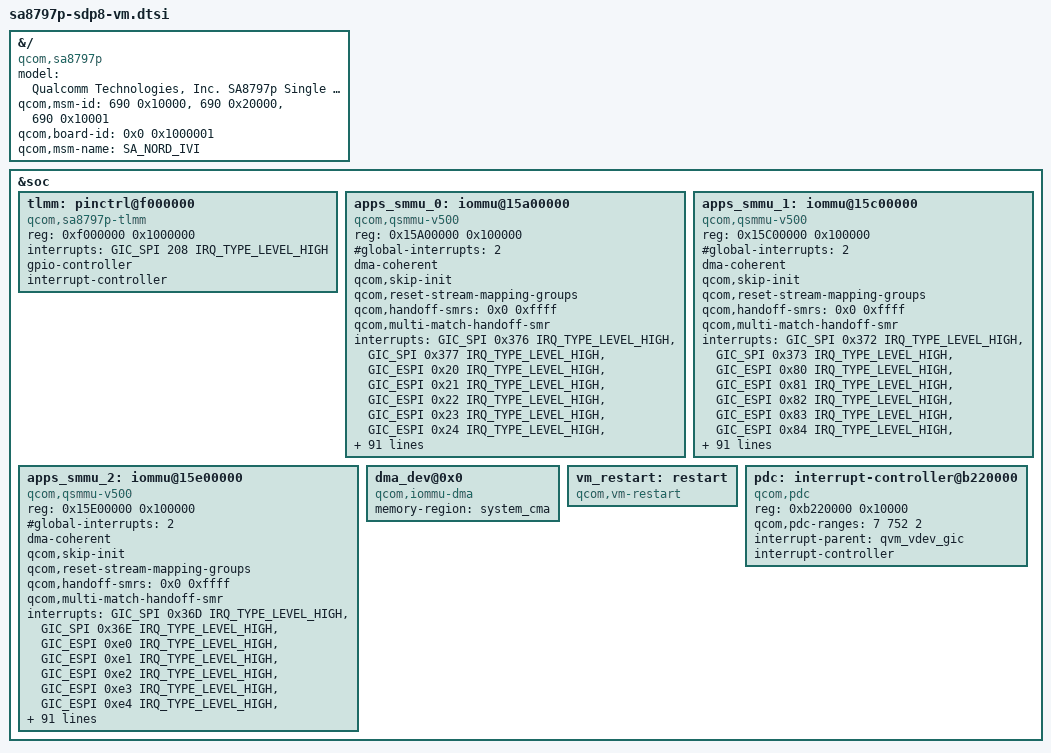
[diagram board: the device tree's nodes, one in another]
// SPDX-License-Identifier: BSD-3-Clause
/*
 * Copyright (c) Qualcomm Technologies, Inc. and/or its subsidiaries.
 */

#include "sdp8-quin-vm-common.dtsi"

&{/} {
	model = "Qualcomm Technologies, Inc. SA8797p Single LA  Guest Virtual Machine";
	compatible = "qcom,sa8797p", "qcom,quinvm";
	qcom,msm-id = <690 0x10000>, <690 0x20000>, <690 0x10001>;
	qcom,board-id = <0x0 0x1000001>;
	qcom,msm-name  = "SA_NORD_IVI";

	#address-cells = <2>;
	#size-cells = <2>;
};

&soc {
	tlmm: pinctrl@f000000 {
		compatible = "qcom,sa8797p-tlmm";
		reg = <0xf000000 0x1000000>;
		interrupts = <GIC_SPI 208 IRQ_TYPE_LEVEL_HIGH>;
		gpio-controller;
		#gpio-cells = <2>;
		interrupt-controller;
		#interrupt-cells = <2>;
	};

	apps_smmu_0: iommu@15a00000 {
		compatible = "qcom,qsmmu-v500";
		reg = <0x15A00000 0x100000>;
		reg-names = "base";
		#iommu-cells = <2>;
		#global-interrupts = <2>;
		dma-coherent;
		qcom,skip-init;
		qcom,reset-stream-mapping-groups;
		qcom,handoff-smrs = <0x0 0xffff>;
		qcom,multi-match-handoff-smr;
		interrupts = <GIC_SPI 0x376 IRQ_TYPE_LEVEL_HIGH>,
				<GIC_SPI 0x377 IRQ_TYPE_LEVEL_HIGH>,
				<GIC_ESPI 0x20 IRQ_TYPE_LEVEL_HIGH>,
				<GIC_ESPI 0x21 IRQ_TYPE_LEVEL_HIGH>,
				<GIC_ESPI 0x22 IRQ_TYPE_LEVEL_HIGH>,
				<GIC_ESPI 0x23 IRQ_TYPE_LEVEL_HIGH>,
				<GIC_ESPI 0x24 IRQ_TYPE_LEVEL_HIGH>,
				<GIC_ESPI 0x25 IRQ_TYPE_LEVEL_HIGH>,
				<GIC_ESPI 0x26 IRQ_TYPE_LEVEL_HIGH>,
				<GIC_ESPI 0x27 IRQ_TYPE_LEVEL_HIGH>,
				<GIC_ESPI 0x28 IRQ_TYPE_LEVEL_HIGH>,
				<GIC_ESPI 0x29 IRQ_TYPE_LEVEL_HIGH>,
				<GIC_ESPI 0x2A IRQ_TYPE_LEVEL_HIGH>,
				<GIC_ESPI 0x2B IRQ_TYPE_LEVEL_HIGH>,
				<GIC_ESPI 0x2C IRQ_TYPE_LEVEL_HIGH>,
				<GIC_ESPI 0x2D IRQ_TYPE_LEVEL_HIGH>,
				<GIC_ESPI 0x2E IRQ_TYPE_LEVEL_HIGH>,
				<GIC_ESPI 0x2F IRQ_TYPE_LEVEL_HIGH>,
				<GIC_ESPI 0x30 IRQ_TYPE_LEVEL_HIGH>,
				<GIC_ESPI 0x31 IRQ_TYPE_LEVEL_HIGH>,
				<GIC_ESPI 0x32 IRQ_TYPE_LEVEL_HIGH>,
				<GIC_ESPI 0x33 IRQ_TYPE_LEVEL_HIGH>,
				<GIC_ESPI 0x34 IRQ_TYPE_LEVEL_HIGH>,
				<GIC_ESPI 0x35 IRQ_TYPE_LEVEL_HIGH>,
				<GIC_ESPI 0x36 IRQ_TYPE_LEVEL_HIGH>,
				<GIC_ESPI 0x37 IRQ_TYPE_LEVEL_HIGH>,
				<GIC_ESPI 0x38 IRQ_TYPE_LEVEL_HIGH>,
				<GIC_ESPI 0x39 IRQ_TYPE_LEVEL_HIGH>,
				<GIC_ESPI 0x3A IRQ_TYPE_LEVEL_HIGH>,
				<GIC_ESPI 0x3B IRQ_TYPE_LEVEL_HIGH>,
				<GIC_ESPI 0x3C IRQ_TYPE_LEVEL_HIGH>,
				<GIC_ESPI 0x3D IRQ_TYPE_LEVEL_HIGH>,
				<GIC_ESPI 0x3E IRQ_TYPE_LEVEL_HIGH>,
				<GIC_ESPI 0x3F IRQ_TYPE_LEVEL_HIGH>,
				<GIC_ESPI 0x40 IRQ_TYPE_LEVEL_HIGH>,
				<GIC_ESPI 0x41 IRQ_TYPE_LEVEL_HIGH>,
				<GIC_ESPI 0x42 IRQ_TYPE_LEVEL_HIGH>,
				<GIC_ESPI 0x43 IRQ_TYPE_LEVEL_HIGH>,
				<GIC_ESPI 0x44 IRQ_TYPE_LEVEL_HIGH>,
				<GIC_ESPI 0x45 IRQ_TYPE_LEVEL_HIGH>,
				<GIC_ESPI 0x46 IRQ_TYPE_LEVEL_HIGH>,
				<GIC_ESPI 0x47 IRQ_TYPE_LEVEL_HIGH>,
				<GIC_ESPI 0x48 IRQ_TYPE_LEVEL_HIGH>,
				<GIC_ESPI 0x49 IRQ_TYPE_LEVEL_HIGH>,
				<GIC_ESPI 0x4A IRQ_TYPE_LEVEL_HIGH>,
				<GIC_ESPI 0x4B IRQ_TYPE_LEVEL_HIGH>,
				<GIC_ESPI 0x4C IRQ_TYPE_LEVEL_HIGH>,
				<GIC_ESPI 0x4D IRQ_TYPE_LEVEL_HIGH>,
				<GIC_ESPI 0x4E IRQ_TYPE_LEVEL_HIGH>,
				<GIC_ESPI 0x4F IRQ_TYPE_LEVEL_HIGH>,
				<GIC_ESPI 0x50 IRQ_TYPE_LEVEL_HIGH>,
				<GIC_ESPI 0x51 IRQ_TYPE_LEVEL_HIGH>,
				<GIC_ESPI 0x52 IRQ_TYPE_LEVEL_HIGH>,
				<GIC_ESPI 0x53 IRQ_TYPE_LEVEL_HIGH>,
				<GIC_ESPI 0x54 IRQ_TYPE_LEVEL_HIGH>,
				<GIC_ESPI 0x55 IRQ_TYPE_LEVEL_HIGH>,
				<GIC_ESPI 0x56 IRQ_TYPE_LEVEL_HIGH>,
				<GIC_ESPI 0x57 IRQ_TYPE_LEVEL_HIGH>,
				<GIC_ESPI 0x58 IRQ_TYPE_LEVEL_HIGH>,
				<GIC_ESPI 0x59 IRQ_TYPE_LEVEL_HIGH>,
				<GIC_ESPI 0x5A IRQ_TYPE_LEVEL_HIGH>,
				<GIC_ESPI 0x5B IRQ_TYPE_LEVEL_HIGH>,
				<GIC_ESPI 0x5C IRQ_TYPE_LEVEL_HIGH>,
				<GIC_ESPI 0x5D IRQ_TYPE_LEVEL_HIGH>,
				<GIC_ESPI 0x5E IRQ_TYPE_LEVEL_HIGH>,
				<GIC_ESPI 0x5F IRQ_TYPE_LEVEL_HIGH>,
				<GIC_ESPI 0x60 IRQ_TYPE_LEVEL_HIGH>,
				<GIC_ESPI 0x61 IRQ_TYPE_LEVEL_HIGH>,
				<GIC_ESPI 0x62 IRQ_TYPE_LEVEL_HIGH>,
				<GIC_ESPI 0x63 IRQ_TYPE_LEVEL_HIGH>,
				<GIC_ESPI 0x64 IRQ_TYPE_LEVEL_HIGH>,
				<GIC_ESPI 0x65 IRQ_TYPE_LEVEL_HIGH>,
				<GIC_ESPI 0x66 IRQ_TYPE_LEVEL_HIGH>,
				<GIC_ESPI 0x67 IRQ_TYPE_LEVEL_HIGH>,
				<GIC_ESPI 0x68 IRQ_TYPE_LEVEL_HIGH>,
				<GIC_ESPI 0x69 IRQ_TYPE_LEVEL_HIGH>,
				<GIC_ESPI 0x6A IRQ_TYPE_LEVEL_HIGH>,
				<GIC_ESPI 0x6B IRQ_TYPE_LEVEL_HIGH>,
				<GIC_ESPI 0x6C IRQ_TYPE_LEVEL_HIGH>,
				<GIC_ESPI 0x6D IRQ_TYPE_LEVEL_HIGH>,
				<GIC_ESPI 0x6E IRQ_TYPE_LEVEL_HIGH>,
				<GIC_ESPI 0x6F IRQ_TYPE_LEVEL_HIGH>,
				<GIC_ESPI 0x70 IRQ_TYPE_LEVEL_HIGH>,
				<GIC_ESPI 0x71 IRQ_TYPE_LEVEL_HIGH>,
				<GIC_ESPI 0x72 IRQ_TYPE_LEVEL_HIGH>,
				<GIC_ESPI 0x73 IRQ_TYPE_LEVEL_HIGH>,
				<GIC_ESPI 0x74 IRQ_TYPE_LEVEL_HIGH>,
				<GIC_ESPI 0x75 IRQ_TYPE_LEVEL_HIGH>,
				<GIC_ESPI 0x76 IRQ_TYPE_LEVEL_HIGH>,
				<GIC_ESPI 0x77 IRQ_TYPE_LEVEL_HIGH>,
				<GIC_ESPI 0x78 IRQ_TYPE_LEVEL_HIGH>,
				<GIC_ESPI 0x79 IRQ_TYPE_LEVEL_HIGH>,
				<GIC_ESPI 0x7A IRQ_TYPE_LEVEL_HIGH>,
				<GIC_ESPI 0x7B IRQ_TYPE_LEVEL_HIGH>,
				<GIC_ESPI 0x7C IRQ_TYPE_LEVEL_HIGH>,
				<GIC_ESPI 0x7D IRQ_TYPE_LEVEL_HIGH>,
				<GIC_ESPI 0x7E IRQ_TYPE_LEVEL_HIGH>,
				<GIC_ESPI 0x7F IRQ_TYPE_LEVEL_HIGH>;
	};

	apps_smmu_1: iommu@15c00000 {
		compatible = "qcom,qsmmu-v500";
		reg = <0x15C00000 0x100000>;
		reg-names = "base";
		#iommu-cells = <2>;
		#global-interrupts = <2>;
		dma-coherent;
		qcom,skip-init;
		qcom,reset-stream-mapping-groups;
		qcom,handoff-smrs = <0x0 0xffff>;
		qcom,multi-match-handoff-smr;
		interrupts = <GIC_SPI  0x372 IRQ_TYPE_LEVEL_HIGH>,
				<GIC_SPI  0x373 IRQ_TYPE_LEVEL_HIGH>,
				<GIC_ESPI 0x80 IRQ_TYPE_LEVEL_HIGH>,
				<GIC_ESPI 0x81 IRQ_TYPE_LEVEL_HIGH>,
				<GIC_ESPI 0x82 IRQ_TYPE_LEVEL_HIGH>,
				<GIC_ESPI 0x83 IRQ_TYPE_LEVEL_HIGH>,
				<GIC_ESPI 0x84 IRQ_TYPE_LEVEL_HIGH>,
				<GIC_ESPI 0x85 IRQ_TYPE_LEVEL_HIGH>,
				<GIC_ESPI 0x86 IRQ_TYPE_LEVEL_HIGH>,
				<GIC_ESPI 0x87 IRQ_TYPE_LEVEL_HIGH>,
				<GIC_ESPI 0x88 IRQ_TYPE_LEVEL_HIGH>,
				<GIC_ESPI 0x89 IRQ_TYPE_LEVEL_HIGH>,
				<GIC_ESPI 0x8a IRQ_TYPE_LEVEL_HIGH>,
				<GIC_ESPI 0x8b IRQ_TYPE_LEVEL_HIGH>,
				<GIC_ESPI 0x8c IRQ_TYPE_LEVEL_HIGH>,
				<GIC_ESPI 0x8d IRQ_TYPE_LEVEL_HIGH>,
				<GIC_ESPI 0x8e IRQ_TYPE_LEVEL_HIGH>,
				<GIC_ESPI 0x8f IRQ_TYPE_LEVEL_HIGH>,
				<GIC_ESPI 0x90 IRQ_TYPE_LEVEL_HIGH>,
				<GIC_ESPI 0x91 IRQ_TYPE_LEVEL_HIGH>,
				<GIC_ESPI 0x92 IRQ_TYPE_LEVEL_HIGH>,
				<GIC_ESPI 0x93 IRQ_TYPE_LEVEL_HIGH>,
				<GIC_ESPI 0x94 IRQ_TYPE_LEVEL_HIGH>,
				<GIC_ESPI 0x95 IRQ_TYPE_LEVEL_HIGH>,
				<GIC_ESPI 0x96 IRQ_TYPE_LEVEL_HIGH>,
				<GIC_ESPI 0x97 IRQ_TYPE_LEVEL_HIGH>,
				<GIC_ESPI 0x98 IRQ_TYPE_LEVEL_HIGH>,
				<GIC_ESPI 0x99 IRQ_TYPE_LEVEL_HIGH>,
				<GIC_ESPI 0x9a IRQ_TYPE_LEVEL_HIGH>,
				<GIC_ESPI 0x9b IRQ_TYPE_LEVEL_HIGH>,
				<GIC_ESPI 0x9c IRQ_TYPE_LEVEL_HIGH>,
				<GIC_ESPI 0x9d IRQ_TYPE_LEVEL_HIGH>,
				<GIC_ESPI 0x9e IRQ_TYPE_LEVEL_HIGH>,
				<GIC_ESPI 0x9f IRQ_TYPE_LEVEL_HIGH>,
				<GIC_ESPI 0xa0 IRQ_TYPE_LEVEL_HIGH>,
				<GIC_ESPI 0xa1 IRQ_TYPE_LEVEL_HIGH>,
				<GIC_ESPI 0xa2 IRQ_TYPE_LEVEL_HIGH>,
				<GIC_ESPI 0xa3 IRQ_TYPE_LEVEL_HIGH>,
				<GIC_ESPI 0xa4 IRQ_TYPE_LEVEL_HIGH>,
				<GIC_ESPI 0xa5 IRQ_TYPE_LEVEL_HIGH>,
				<GIC_ESPI 0xa6 IRQ_TYPE_LEVEL_HIGH>,
				<GIC_ESPI 0xa7 IRQ_TYPE_LEVEL_HIGH>,
				<GIC_ESPI 0xa8 IRQ_TYPE_LEVEL_HIGH>,
				<GIC_ESPI 0xa9 IRQ_TYPE_LEVEL_HIGH>,
				<GIC_ESPI 0xaa IRQ_TYPE_LEVEL_HIGH>,
				<GIC_ESPI 0xab IRQ_TYPE_LEVEL_HIGH>,
				<GIC_ESPI 0xac IRQ_TYPE_LEVEL_HIGH>,
				<GIC_ESPI 0xad IRQ_TYPE_LEVEL_HIGH>,
				<GIC_ESPI 0xae IRQ_TYPE_LEVEL_HIGH>,
				<GIC_ESPI 0xaf IRQ_TYPE_LEVEL_HIGH>,
				<GIC_ESPI 0xb0 IRQ_TYPE_LEVEL_HIGH>,
				<GIC_ESPI 0xb1 IRQ_TYPE_LEVEL_HIGH>,
				<GIC_ESPI 0xb2 IRQ_TYPE_LEVEL_HIGH>,
				<GIC_ESPI 0xb3 IRQ_TYPE_LEVEL_HIGH>,
				<GIC_ESPI 0xb4 IRQ_TYPE_LEVEL_HIGH>,
				<GIC_ESPI 0xb5 IRQ_TYPE_LEVEL_HIGH>,
				<GIC_ESPI 0xb6 IRQ_TYPE_LEVEL_HIGH>,
				<GIC_ESPI 0xb7 IRQ_TYPE_LEVEL_HIGH>,
				<GIC_ESPI 0xb8 IRQ_TYPE_LEVEL_HIGH>,
				<GIC_ESPI 0xb9 IRQ_TYPE_LEVEL_HIGH>,
				<GIC_ESPI 0xba IRQ_TYPE_LEVEL_HIGH>,
				<GIC_ESPI 0xbb IRQ_TYPE_LEVEL_HIGH>,
				<GIC_ESPI 0xbc IRQ_TYPE_LEVEL_HIGH>,
				<GIC_ESPI 0xbd IRQ_TYPE_LEVEL_HIGH>,
				<GIC_ESPI 0xbe IRQ_TYPE_LEVEL_HIGH>,
				<GIC_ESPI 0xbf IRQ_TYPE_LEVEL_HIGH>,
				<GIC_ESPI 0xc0 IRQ_TYPE_LEVEL_HIGH>,
				<GIC_ESPI 0xc1 IRQ_TYPE_LEVEL_HIGH>,
				<GIC_ESPI 0xc2 IRQ_TYPE_LEVEL_HIGH>,
				<GIC_ESPI 0xc3 IRQ_TYPE_LEVEL_HIGH>,
				<GIC_ESPI 0xc4 IRQ_TYPE_LEVEL_HIGH>,
				<GIC_ESPI 0xc5 IRQ_TYPE_LEVEL_HIGH>,
				<GIC_ESPI 0xc6 IRQ_TYPE_LEVEL_HIGH>,
				<GIC_ESPI 0xc7 IRQ_TYPE_LEVEL_HIGH>,
				<GIC_ESPI 0xc8 IRQ_TYPE_LEVEL_HIGH>,
				<GIC_ESPI 0xc9 IRQ_TYPE_LEVEL_HIGH>,
				<GIC_ESPI 0xca IRQ_TYPE_LEVEL_HIGH>,
				<GIC_ESPI 0xcb IRQ_TYPE_LEVEL_HIGH>,
				<GIC_ESPI 0xcc IRQ_TYPE_LEVEL_HIGH>,
				<GIC_ESPI 0xcd IRQ_TYPE_LEVEL_HIGH>,
				<GIC_ESPI 0xce IRQ_TYPE_LEVEL_HIGH>,
				<GIC_ESPI 0xcf IRQ_TYPE_LEVEL_HIGH>,
				<GIC_ESPI 0xd0 IRQ_TYPE_LEVEL_HIGH>,
				<GIC_ESPI 0xd1 IRQ_TYPE_LEVEL_HIGH>,
				<GIC_ESPI 0xd2 IRQ_TYPE_LEVEL_HIGH>,
				<GIC_ESPI 0xd3 IRQ_TYPE_LEVEL_HIGH>,
				<GIC_ESPI 0xd4 IRQ_TYPE_LEVEL_HIGH>,
				<GIC_ESPI 0xd5 IRQ_TYPE_LEVEL_HIGH>,
				<GIC_ESPI 0xd6 IRQ_TYPE_LEVEL_HIGH>,
				<GIC_ESPI 0xd7 IRQ_TYPE_LEVEL_HIGH>,
				<GIC_ESPI 0xd8 IRQ_TYPE_LEVEL_HIGH>,
				<GIC_ESPI 0xd9 IRQ_TYPE_LEVEL_HIGH>,
				<GIC_ESPI 0xda IRQ_TYPE_LEVEL_HIGH>,
				<GIC_ESPI 0xdb IRQ_TYPE_LEVEL_HIGH>,
				<GIC_ESPI 0xdc IRQ_TYPE_LEVEL_HIGH>,
				<GIC_ESPI 0xdd IRQ_TYPE_LEVEL_HIGH>,
				<GIC_ESPI 0xde IRQ_TYPE_LEVEL_HIGH>,
				<GIC_ESPI 0xdf IRQ_TYPE_LEVEL_HIGH>;
	};

	apps_smmu_2: iommu@15e00000 {
		compatible = "qcom,qsmmu-v500";
		reg = <0x15E00000 0x100000>;
		reg-names = "base";
		#iommu-cells = <2>;
		#global-interrupts = <2>;
		dma-coherent;
		qcom,skip-init;
		qcom,reset-stream-mapping-groups;
		qcom,handoff-smrs = <0x0 0xffff>;
		qcom,multi-match-handoff-smr;
		interrupts = <GIC_SPI  0x36D IRQ_TYPE_LEVEL_HIGH>,
				<GIC_SPI  0x36E IRQ_TYPE_LEVEL_HIGH>,
				<GIC_ESPI 0xe0 IRQ_TYPE_LEVEL_HIGH>,
				<GIC_ESPI 0xe1 IRQ_TYPE_LEVEL_HIGH>,
				<GIC_ESPI 0xe2 IRQ_TYPE_LEVEL_HIGH>,
				<GIC_ESPI 0xe3 IRQ_TYPE_LEVEL_HIGH>,
				<GIC_ESPI 0xe4 IRQ_TYPE_LEVEL_HIGH>,
				<GIC_ESPI 0xe5 IRQ_TYPE_LEVEL_HIGH>,
				<GIC_ESPI 0xe6 IRQ_TYPE_LEVEL_HIGH>,
				<GIC_ESPI 0xe7 IRQ_TYPE_LEVEL_HIGH>,
				<GIC_ESPI 0xe8 IRQ_TYPE_LEVEL_HIGH>,
				<GIC_ESPI 0xe9 IRQ_TYPE_LEVEL_HIGH>,
				<GIC_ESPI 0xea IRQ_TYPE_LEVEL_HIGH>,
				<GIC_ESPI 0xeb IRQ_TYPE_LEVEL_HIGH>,
				<GIC_ESPI 0xec IRQ_TYPE_LEVEL_HIGH>,
				<GIC_ESPI 0xed IRQ_TYPE_LEVEL_HIGH>,
				<GIC_ESPI 0xee IRQ_TYPE_LEVEL_HIGH>,
				<GIC_ESPI 0xef IRQ_TYPE_LEVEL_HIGH>,
				<GIC_ESPI 0xf0 IRQ_TYPE_LEVEL_HIGH>,
				<GIC_ESPI 0xf1 IRQ_TYPE_LEVEL_HIGH>,
				<GIC_ESPI 0xf2 IRQ_TYPE_LEVEL_HIGH>,
				<GIC_ESPI 0xf3 IRQ_TYPE_LEVEL_HIGH>,
				<GIC_ESPI 0xf4 IRQ_TYPE_LEVEL_HIGH>,
				<GIC_ESPI 0xf5 IRQ_TYPE_LEVEL_HIGH>,
				<GIC_ESPI 0xf6 IRQ_TYPE_LEVEL_HIGH>,
				<GIC_ESPI 0xf7 IRQ_TYPE_LEVEL_HIGH>,
				<GIC_ESPI 0xf8 IRQ_TYPE_LEVEL_HIGH>,
				<GIC_ESPI 0xf9 IRQ_TYPE_LEVEL_HIGH>,
				<GIC_ESPI 0xfa IRQ_TYPE_LEVEL_HIGH>,
				<GIC_ESPI 0xfb IRQ_TYPE_LEVEL_HIGH>,
				<GIC_ESPI 0xfc IRQ_TYPE_LEVEL_HIGH>,
				<GIC_ESPI 0xfd IRQ_TYPE_LEVEL_HIGH>,
				<GIC_ESPI 0xfe IRQ_TYPE_LEVEL_HIGH>,
				<GIC_ESPI 0xff IRQ_TYPE_LEVEL_HIGH>,
				<GIC_ESPI 0x100 IRQ_TYPE_LEVEL_HIGH>,
				<GIC_ESPI 0x101 IRQ_TYPE_LEVEL_HIGH>,
				<GIC_ESPI 0x102 IRQ_TYPE_LEVEL_HIGH>,
				<GIC_ESPI 0x103 IRQ_TYPE_LEVEL_HIGH>,
				<GIC_ESPI 0x104 IRQ_TYPE_LEVEL_HIGH>,
				<GIC_ESPI 0x105 IRQ_TYPE_LEVEL_HIGH>,
				<GIC_ESPI 0x106 IRQ_TYPE_LEVEL_HIGH>,
				<GIC_ESPI 0x107 IRQ_TYPE_LEVEL_HIGH>,
				<GIC_ESPI 0x108 IRQ_TYPE_LEVEL_HIGH>,
				<GIC_ESPI 0x109 IRQ_TYPE_LEVEL_HIGH>,
				<GIC_ESPI 0x10a IRQ_TYPE_LEVEL_HIGH>,
				<GIC_ESPI 0x10b IRQ_TYPE_LEVEL_HIGH>,
				<GIC_ESPI 0x10c IRQ_TYPE_LEVEL_HIGH>,
				<GIC_ESPI 0x10d IRQ_TYPE_LEVEL_HIGH>,
				<GIC_ESPI 0x10e IRQ_TYPE_LEVEL_HIGH>,
				<GIC_ESPI 0x10f IRQ_TYPE_LEVEL_HIGH>,
				<GIC_ESPI 0x110 IRQ_TYPE_LEVEL_HIGH>,
				<GIC_ESPI 0x111 IRQ_TYPE_LEVEL_HIGH>,
				<GIC_ESPI 0x112 IRQ_TYPE_LEVEL_HIGH>,
				<GIC_ESPI 0x113 IRQ_TYPE_LEVEL_HIGH>,
				<GIC_ESPI 0x114 IRQ_TYPE_LEVEL_HIGH>,
				<GIC_ESPI 0x115 IRQ_TYPE_LEVEL_HIGH>,
				<GIC_ESPI 0x116 IRQ_TYPE_LEVEL_HIGH>,
				<GIC_ESPI 0x117 IRQ_TYPE_LEVEL_HIGH>,
				<GIC_ESPI 0x118 IRQ_TYPE_LEVEL_HIGH>,
				<GIC_ESPI 0x119 IRQ_TYPE_LEVEL_HIGH>,
				<GIC_ESPI 0x11a IRQ_TYPE_LEVEL_HIGH>,
				<GIC_ESPI 0x11b IRQ_TYPE_LEVEL_HIGH>,
				<GIC_ESPI 0x11c IRQ_TYPE_LEVEL_HIGH>,
				<GIC_ESPI 0x11d IRQ_TYPE_LEVEL_HIGH>,
				<GIC_ESPI 0x11e IRQ_TYPE_LEVEL_HIGH>,
				<GIC_ESPI 0x11f IRQ_TYPE_LEVEL_HIGH>,
				<GIC_ESPI 0x120 IRQ_TYPE_LEVEL_HIGH>,
				<GIC_ESPI 0x121 IRQ_TYPE_LEVEL_HIGH>,
				<GIC_ESPI 0x122 IRQ_TYPE_LEVEL_HIGH>,
				<GIC_ESPI 0x123 IRQ_TYPE_LEVEL_HIGH>,
				<GIC_ESPI 0x124 IRQ_TYPE_LEVEL_HIGH>,
				<GIC_ESPI 0x125 IRQ_TYPE_LEVEL_HIGH>,
				<GIC_ESPI 0x126 IRQ_TYPE_LEVEL_HIGH>,
				<GIC_ESPI 0x127 IRQ_TYPE_LEVEL_HIGH>,
				<GIC_ESPI 0x128 IRQ_TYPE_LEVEL_HIGH>,
				<GIC_ESPI 0x129 IRQ_TYPE_LEVEL_HIGH>,
				<GIC_ESPI 0x12a IRQ_TYPE_LEVEL_HIGH>,
				<GIC_ESPI 0x12b IRQ_TYPE_LEVEL_HIGH>,
				<GIC_ESPI 0x12c IRQ_TYPE_LEVEL_HIGH>,
				<GIC_ESPI 0x12d IRQ_TYPE_LEVEL_HIGH>,
				<GIC_ESPI 0x12e IRQ_TYPE_LEVEL_HIGH>,
				<GIC_ESPI 0x12f IRQ_TYPE_LEVEL_HIGH>,
				<GIC_ESPI 0x130 IRQ_TYPE_LEVEL_HIGH>,
				<GIC_ESPI 0x131 IRQ_TYPE_LEVEL_HIGH>,
				<GIC_ESPI 0x132 IRQ_TYPE_LEVEL_HIGH>,
				<GIC_ESPI 0x133 IRQ_TYPE_LEVEL_HIGH>,
				<GIC_ESPI 0x134 IRQ_TYPE_LEVEL_HIGH>,
				<GIC_ESPI 0x135 IRQ_TYPE_LEVEL_HIGH>,
				<GIC_ESPI 0x136 IRQ_TYPE_LEVEL_HIGH>,
				<GIC_ESPI 0x137 IRQ_TYPE_LEVEL_HIGH>,
				<GIC_ESPI 0x138 IRQ_TYPE_LEVEL_HIGH>,
				<GIC_ESPI 0x139 IRQ_TYPE_LEVEL_HIGH>,
				<GIC_ESPI 0x13a IRQ_TYPE_LEVEL_HIGH>,
				<GIC_ESPI 0x13b IRQ_TYPE_LEVEL_HIGH>,
				<GIC_ESPI 0x13c IRQ_TYPE_LEVEL_HIGH>,
				<GIC_ESPI 0x13d IRQ_TYPE_LEVEL_HIGH>,
				<GIC_ESPI 0x13e IRQ_TYPE_LEVEL_HIGH>,
				<GIC_ESPI 0x13f IRQ_TYPE_LEVEL_HIGH>;
	};

	dma_dev@0x0 {
		compatible = "qcom,iommu-dma";
		memory-region = <&system_cma>;
	};

	vm_restart: restart {
		compatible = "qcom,vm-restart";
		status = "ok";
	};

	pdc: interrupt-controller@b220000 {
		compatible = "qcom,pdc";
		reg = <0xb220000 0x10000>;
		qcom,pdc-ranges = <7 752 2>;
		#interrupt-cells = <2>;
		interrupt-parent = <&qvm_vdev_gic>;
		interrupt-controller;
	};
};

#include "sa8797p-pinctrl.dtsi"
#include "sa8797p-vm-qupv3.dtsi"
#include "sa8797p-vm-usb.dtsi"
